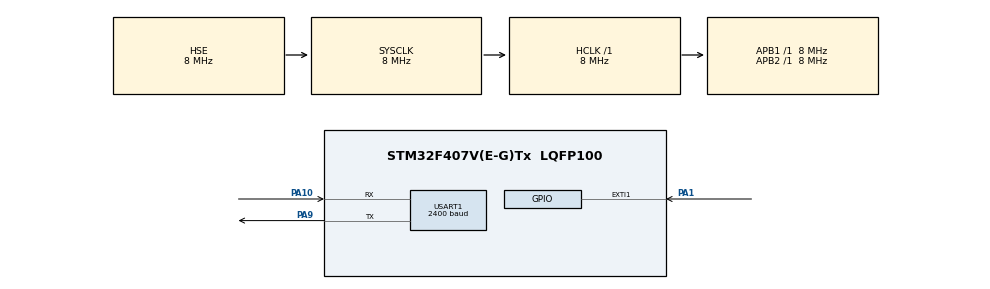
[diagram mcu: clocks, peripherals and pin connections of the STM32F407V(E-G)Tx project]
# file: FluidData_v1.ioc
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Mcu.Family=STM32F4
Mcu.Name=STM32F407V(E-G)Tx
Mcu.Package=LQFP100
NVIC.EXTI1_IRQn=true\:2\:0\:true\:false\:true
NVIC.PriorityGroup=NVIC_PRIORITYGROUP_4
NVIC.TIM4_IRQn=true\:0\:0\:true\:false\:true
PA1.Signal=GPXTI1
PA10.Mode=Asynchronous
PA10.Signal=USART1_RX
PA9.Mode=Asynchronous
PA9.Signal=USART1_TX
PH0-OSC_IN.Mode=HSE-External-Oscillator
PH0-OSC_IN.Signal=RCC_OSC_IN
PH1-OSC_OUT.Mode=HSE-External-Oscillator
PH1-OSC_OUT.Signal=RCC_OSC_OUT
ProjectManager.HeapSize=0x200
ProjectManager.StackSize=0x400
ProjectManager.TargetToolchain=SW4STM32
RCC.48MHZClocksFreq_Value=24000000
RCC.AHBFreq_Value=8000000
RCC.APB1Freq_Value=8000000
RCC.APB1TimFreq_Value=8000000
RCC.APB2Freq_Value=8000000
RCC.APB2TimFreq_Value=8000000
RCC.CortexFreq_Value=8000000
RCC.HCLKFreq_Value=8000000
RCC.HSE_VALUE=8000000
RCC.HSI_VALUE=16000000
RCC.LSE_VALUE=32768
RCC.PLLSourceVirtual=RCC_PLLSOURCE_HSE
RCC.SYSCLKFreq_VALUE=8000000
RCC.SYSCLKSource=RCC_SYSCLKSOURCE_HSE
RCC.VCOOutputFreq_Value=96000000
TIM4.Channel-Output\ Compare2\ No\ Output=TIM_CHANNEL_2
TIM4.Period=7999
USART1.BaudRate=2400
VP_TIM4_VS_no_output2.Mode=Output Compare2 No Output
board=FluidData_v1

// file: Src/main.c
/**
  ******************************************************************************
  * File Name          : main.c
  * Description        : Main program body
  ******************************************************************************
  *
  * COPYRIGHT(c) 2016 STMicroelectronics
  *
  * Redistribution and use in source and binary forms, with or without modification,
  * are permitted provided that the following conditions are met:
  *   1. Redistributions of source code must retain the above copyright notice,
  *      this list of conditions and the following disclaimer.
  *   2. Redistributions in binary form must reproduce the above copyright notice,
  *      this list of conditions and the following disclaimer in the documentation
  *      and/or other materials provided with the distribution.
  *   3. Neither the name of STMicroelectronics nor the names of its contributors
  *      may be used to endorse or promote products derived from this software
  *      without specific prior written permission.
  *
  * THIS SOFTWARE IS PROVIDED BY THE COPYRIGHT HOLDERS AND CONTRIBUTORS "AS IS"
  * AND ANY EXPRESS OR IMPLIED WARRANTIES, INCLUDING, BUT NOT LIMITED TO, THE
  * IMPLIED WARRANTIES OF MERCHANTABILITY AND FITNESS FOR A PARTICULAR PURPOSE ARE
  * DISCLAIMED. IN NO EVENT SHALL THE COPYRIGHT HOLDER OR CONTRIBUTORS BE LIABLE
  * FOR ANY DIRECT, INDIRECT, INCIDENTAL, SPECIAL, EXEMPLARY, OR CONSEQUENTIAL
  * DAMAGES (INCLUDING, BUT NOT LIMITED TO, PROCUREMENT OF SUBSTITUTE GOODS OR
  * SERVICES; LOSS OF USE, DATA, OR PROFITS; OR BUSINESS INTERRUPTION) HOWEVER
  * CAUSED AND ON ANY THEORY OF LIABILITY, WHETHER IN CONTRACT, STRICT LIABILITY,
  * OR TORT (INCLUDING NEGLIGENCE OR OTHERWISE) ARISING IN ANY WAY OUT OF THE USE
  * OF THIS SOFTWARE, EVEN IF ADVISED OF THE POSSIBILITY OF SUCH DAMAGE.
  *
  ******************************************************************************
  */
#include "main.h"
#include "stm32f4xx_hal.h"
#include <stdio.h>

TIM_HandleTypeDef htim4;

UART_HandleTypeDef huart1;

/* USER CODE BEGIN PV */
/* Private variables ---------------------------------------------------------*/
uint8_t aTxBuffer[11];
uint8_t result[8];
int TIMER, COUNT,END, i =0;

/* USER CODE END PV */

void SystemClock_Config(void);
void Error_Handler(void);
static void MX_GPIO_Init(void);
static void MX_TIM4_Init(void);
static void MX_USART1_UART_Init(void);
void TIM4_IRQHandler(void);
void HAL_GPIO_EXTI_Callback(uint16_t GPIO_Pin);
void DumpHex(const void* data, size_t size);
/* USER CODE BEGIN PFP */
/* Private function prototypes -----------------------------------------------*/

/* USER CODE END PFP */

int main(void)
{

  /* MCU Configuration----------------------------------------------------------*/

  /* Reset of all peripherals, Initializes the Flash interface and the Systick. */
  HAL_Init();

  /* Configure the system clock */
  SystemClock_Config();

  /* Initialize all configured peripherals */
  MX_GPIO_Init();
  MX_TIM4_Init();
  MX_USART1_UART_Init();

  /* USER CODE BEGIN 2 */
  //to init he array in C we use memset function
  memset(result,0,sizeof(result));
  /* USER CODE END 2 */

  /* Infinite loop */
  while (1)
  {

  }

}

/** System Clock Configuration
*/
void SystemClock_Config(void)
{

  RCC_OscInitTypeDef RCC_OscInitStruct;
  RCC_ClkInitTypeDef RCC_ClkInitStruct;

    /**Configure the main internal regulator output voltage
    */
  __HAL_RCC_PWR_CLK_ENABLE();

  __HAL_PWR_VOLTAGESCALING_CONFIG(PWR_REGULATOR_VOLTAGE_SCALE1);

    /**Initializes the CPU, AHB and APB busses clocks
    */
  RCC_OscInitStruct.OscillatorType = RCC_OSCILLATORTYPE_HSE;
  RCC_OscInitStruct.HSEState = RCC_HSE_ON;
  RCC_OscInitStruct.PLL.PLLState = RCC_PLL_NONE;
  if (HAL_RCC_OscConfig(&RCC_OscInitStruct) != HAL_OK)
  {
    Error_Handler();
  }

    /**Initializes the CPU, AHB and APB busses clocks
    */
  RCC_ClkInitStruct.ClockType = RCC_CLOCKTYPE_HCLK|RCC_CLOCKTYPE_SYSCLK
                              |RCC_CLOCKTYPE_PCLK1|RCC_CLOCKTYPE_PCLK2;
  RCC_ClkInitStruct.SYSCLKSource = RCC_SYSCLKSOURCE_HSE;
  RCC_ClkInitStruct.AHBCLKDivider = RCC_SYSCLK_DIV1;
  RCC_ClkInitStruct.APB1CLKDivider = RCC_HCLK_DIV1;
  RCC_ClkInitStruct.APB2CLKDivider = RCC_HCLK_DIV1;

  if (HAL_RCC_ClockConfig(&RCC_ClkInitStruct, FLASH_LATENCY_0) != HAL_OK)
  {
    Error_Handler();
  }

    /**Configure the Systick interrupt time
    */
  HAL_SYSTICK_Config(HAL_RCC_GetHCLKFreq()/1000);

    /**Configure the Systick
    */
  HAL_SYSTICK_CLKSourceConfig(SYSTICK_CLKSOURCE_HCLK);

  /* SysTick_IRQn interrupt configuration */
  HAL_NVIC_SetPriority(SysTick_IRQn, 0, 0);
}

/* TIM4 init function */
static void MX_TIM4_Init(void)
{

  TIM_MasterConfigTypeDef sMasterConfig;
  TIM_OC_InitTypeDef sConfigOC;

  htim4.Instance = TIM4;
  htim4.Init.Prescaler = 1000;
  htim4.Init.CounterMode = TIM_COUNTERMODE_UP;
  htim4.Init.Period = 23976; //ticks every 3500ms
  htim4.Init.ClockDivision = TIM_CLOCKDIVISION_DIV1;
  if (HAL_TIM_OC_Init(&htim4) != HAL_OK)
  {
    Error_Handler();
  }

  sMasterConfig.MasterOutputTrigger = TIM_TRGO_RESET;
  sMasterConfig.MasterSlaveMode = TIM_MASTERSLAVEMODE_DISABLE;
  if (HAL_TIMEx_MasterConfigSynchronization(&htim4, &sMasterConfig) != HAL_OK)
  {
    Error_Handler();
  }

  sConfigOC.OCMode = TIM_OCMODE_TIMING;
  sConfigOC.Pulse = 0;
  sConfigOC.OCPolarity = TIM_OCPOLARITY_HIGH;
  sConfigOC.OCFastMode = TIM_OCFAST_DISABLE;
  if (HAL_TIM_OC_ConfigChannel(&htim4, &sConfigOC, TIM_CHANNEL_2) != HAL_OK)
  {
    Error_Handler();
  }

}

//Will Handle timeout between each bit
void TIM4_IRQHandler(void){

	 if( __HAL_TIM_CLEAR_FLAG(&htim4, TIM_FLAG_UPDATE)!= RESET){
		 if (__HAL_TIM_GET_ITSTATUS(&htim4, TIM_IT_UPDATE) != RESET)
		         {
		             __HAL_TIM_CLEAR_FLAG(&htim4, TIM_FLAG_UPDATE);

		             if(COUNT >= 20){
		             		   COUNT = 0;
		             		   result[i]='1';
		             		   TIMER = 0;
		             		  if(i==7){
		             			  int value =(int)strtol(result, NULL,2);
		             			  DumpHex(&value,sizeof(value));
								  i=0;
								}else{
									 i++;
								 }
		             		 HAL_TIM_Base_Stop(&htim4);// Stop TIM4
		             }else if((COUNT < 20)&&(COUNT != 0)){
		             	 	   COUNT = 0;
		             		   result[i]='0';
		             		   TIMER = 0;
		             		  if(i==7){
		             			  int value = (int)strtol(result, NULL,2);
		             			 DumpHex(&value,sizeof(value));
		             			  i=0;
		             			  }else{
									 i++;
								 }
		             		   HAL_TIM_Base_Stop(&htim4);// Stop TIM4

		             }
				}
	 }
}

/**
  * @brief EXTI line detection callbacks
  * @param GPIO_Pin: Specifies the pins connected EXTI line
  * @retval None
  */
void HAL_GPIO_EXTI_Callback(uint16_t GPIO_Pin)
{
  if(GPIO_Pin == GPIO_PIN_1)
  {

	   if(TIMER==0){
		   //Start TIM4
	     HAL_TIM_Base_Start_IT(&htim4); // start timer interrupts
		 HAL_NVIC_SetPriority(TIM4_IRQn, 0, 1);
		 HAL_NVIC_EnableIRQ(TIM4_IRQn);
	   }
	   COUNT++;
  }
}

/* USART1 init function */
static void MX_USART1_UART_Init(void)
{

  huart1.Instance = USART1;
  huart1.Init.BaudRate = 2400;
  huart1.Init.WordLength = UART_WORDLENGTH_8B;
  huart1.Init.StopBits = UART_STOPBITS_1;
  huart1.Init.Parity = UART_PARITY_NONE;
  huart1.Init.Mode = UART_MODE_TX_RX;
  huart1.Init.HwFlowCtl = UART_HWCONTROL_NONE;
  huart1.Init.OverSampling = UART_OVERSAMPLING_16;
  if (HAL_UART_Init(&huart1) != HAL_OK)
  {
    Error_Handler();
  }

}

/** Configure pins as
        * Analog
        * Input
        * Output
        * EVENT_OUT
        * EXTI
*/
static void MX_GPIO_Init(void)
{

  GPIO_InitTypeDef GPIO_InitStruct;

  /* GPIO Ports Clock Enable */
  __HAL_RCC_GPIOH_CLK_ENABLE();
  __HAL_RCC_GPIOA_CLK_ENABLE();
  __HAL_RCC_GPIOC_CLK_ENABLE();

  GPIO_InitStruct.Alternate = GPIO_AF7_USART1;
    GPIO_InitStruct.Mode = GPIO_MODE_AF_PP;
    GPIO_InitStruct.Pin = GPIO_PIN_9;
    GPIO_InitStruct.Pull = GPIO_NOPULL;
    HAL_GPIO_Init(GPIOA,&GPIO_InitStruct);

    GPIO_InitStruct.Alternate = GPIO_AF7_USART1;
    GPIO_InitStruct.Mode = GPIO_MODE_AF_PP;
    GPIO_InitStruct.Pin = GPIO_PIN_10;
    GPIO_InitStruct.Pull = GPIO_NOPULL;
    HAL_GPIO_Init(GPIOA,&GPIO_InitStruct);

    GPIO_InitStruct.Pin = GPIO_PIN_9;
    GPIO_InitStruct.Mode = GPIO_MODE_OUTPUT_PP;
    GPIO_InitStruct.Pull = GPIO_NOPULL;
    HAL_GPIO_Init(GPIOC,&GPIO_InitStruct);

  /*Configure GPIO pin : PA1 */
  GPIO_InitStruct.Pin = GPIO_PIN_1;
  GPIO_InitStruct.Mode = GPIO_MODE_IT_RISING;
  GPIO_InitStruct.Pull = GPIO_NOPULL;
  HAL_GPIO_Init(GPIOA, &GPIO_InitStruct);

  /* EXTI interrupt init*/
  HAL_NVIC_SetPriority(EXTI1_IRQn, 2, 0);
  HAL_NVIC_EnableIRQ(EXTI1_IRQn);

}

/* USER CODE BEGIN 4 */
void DumpHex(const void* data, size_t size) {
	char ascii[17];
	size_t i;
	ascii[16] = '\0';
	for (i = 0; i < size; ++i) {
		if (((unsigned char*)data)[i] >= ' ' && ((unsigned char*)data)[i] <= '~') {
			ascii[i % 16] = ((unsigned char*)data)[i];
		} else {
			ascii[i % 16] = '.';
		}
		if ((i+1) % 8 == 0 || i+1 == size) {
			    if (i+1 == size) {
				ascii[(i+1) % 16] = '\0';
				sprintf(aTxBuffer,"%s\r\n", ascii);
				 HAL_UART_Transmit(&huart1, aTxBuffer , sizeof(aTxBuffer)/sizeof(*aTxBuffer), 1000);
			}
		}
	}
}
/* USER CODE END 4 */

void Error_Handler(void)
{
  while(1)
  {
  }
}

/************************ (C) COPYRIGHT STMicroelectronics *****END OF FILE****/
